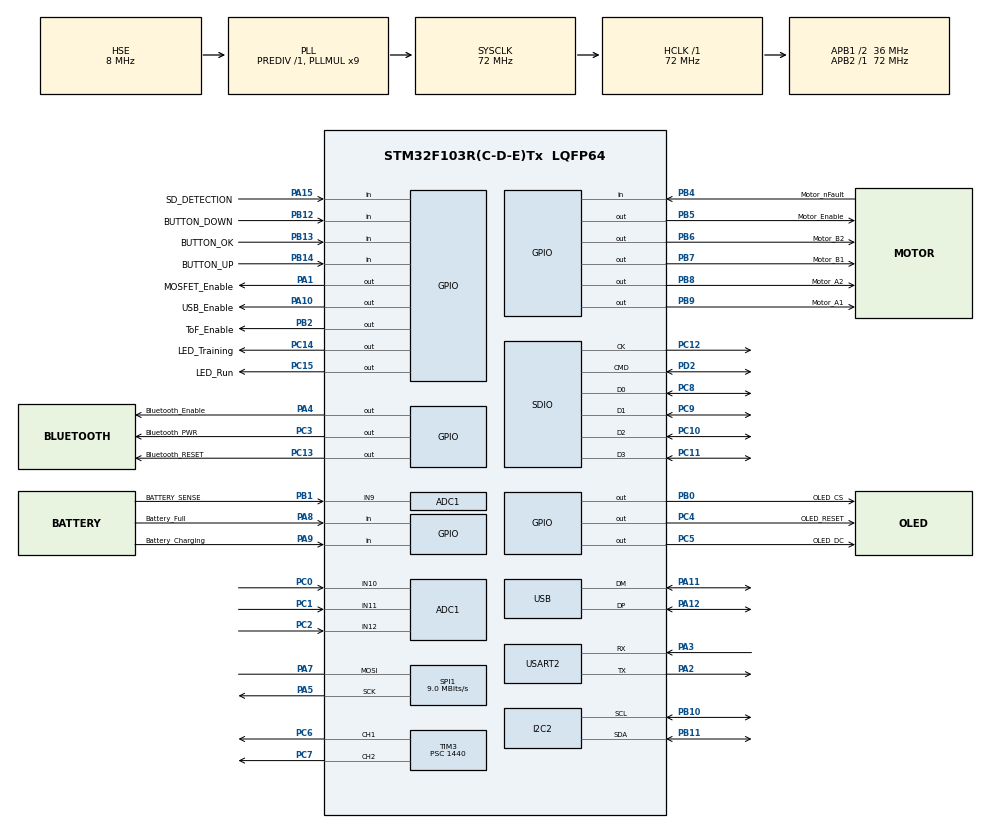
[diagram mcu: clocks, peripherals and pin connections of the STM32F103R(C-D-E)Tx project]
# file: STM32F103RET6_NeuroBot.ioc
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ADC1.Channel-0\#ChannelRegularConversion=ADC_CHANNEL_9
ADC1.Channel-1\#ChannelRegularConversion=ADC_CHANNEL_10
ADC1.Channel-2\#ChannelRegularConversion=ADC_CHANNEL_11
ADC1.Channel-3\#ChannelRegularConversion=ADC_CHANNEL_12
ADC1.ContinuousConvMode=ENABLE
ADC1.DataAlign=ADC_DATAALIGN_RIGHT
ADC1.DiscontinuousConvMode=DISABLE
ADC1.EnableAnalogWatchDog=false
ADC1.EnableRegularConversion=ENABLE
ADC1.ExternalTrigConv=ADC_SOFTWARE_START
ADC1.InjNumberOfConversion=0
ADC1.NbrOfConversion=4
ADC1.NbrOfConversionFlag=1
ADC1.Rank-0\#ChannelRegularConversion=1
ADC1.Rank-1\#ChannelRegularConversion=2
ADC1.Rank-2\#ChannelRegularConversion=3
ADC1.Rank-3\#ChannelRegularConversion=4
ADC1.SamplingTime-0\#ChannelRegularConversion=ADC_SAMPLETIME_239CYCLES_5
ADC1.SamplingTime-1\#ChannelRegularConversion=ADC_SAMPLETIME_239CYCLES_5
ADC1.SamplingTime-2\#ChannelRegularConversion=ADC_SAMPLETIME_239CYCLES_5
ADC1.SamplingTime-3\#ChannelRegularConversion=ADC_SAMPLETIME_239CYCLES_5
ADC1.ScanConvMode=ADC_SCAN_ENABLE
ADC1.master=1
Dma.ADC1.0.Direction=DMA_PERIPH_TO_MEMORY
Dma.ADC1.0.Instance=DMA1_Channel1
Dma.ADC1.0.MemDataAlignment=DMA_MDATAALIGN_WORD
Dma.ADC1.0.MemInc=DMA_MINC_ENABLE
Dma.ADC1.0.Mode=DMA_CIRCULAR
Dma.ADC1.0.PeriphDataAlignment=DMA_PDATAALIGN_WORD
Dma.ADC1.0.PeriphInc=DMA_PINC_DISABLE
Dma.ADC1.0.Priority=DMA_PRIORITY_LOW
Dma.Request0=ADC1
Mcu.Family=STM32F1
Mcu.Name=STM32F103R(C-D-E)Tx
Mcu.Package=LQFP64
NVIC.ADC1_2_IRQn=true\:0\:0\:false\:false\:true\:true
NVIC.DMA1_Channel1_IRQn=true\:0\:0\:false\:false\:true\:false
NVIC.PriorityGroup=NVIC_PRIORITYGROUP_4
NVIC.SDIO_IRQn=true\:0\:0\:false\:false\:true\:true
NVIC.TIM2_IRQn=true\:0\:0\:false\:false\:true\:true
NVIC.USART2_IRQn=true\:0\:0\:false\:false\:true\:true
NVIC.USB_LP_CAN1_RX0_IRQn=true\:0\:0\:false\:false\:true\:true
PA0-WKUP.GPIO_Label=POWER_ON_MAIN
PA0-WKUP.Mode=SYS_WakeUp0
PA0-WKUP.Signal=SYS_WKUP
PA1.GPIO_Label=MOSFET_Enable
PA1.GPIO_Speed=GPIO_SPEED_FREQ_HIGH
PA1.Signal=GPIO_Output
PA10.GPIO_Label=USB_Enable
PA10.GPIO_Speed=GPIO_SPEED_FREQ_HIGH
PA10.Signal=GPIO_Output
PA11.Mode=Device
PA11.Signal=USB_DM
PA12.Mode=Device
PA12.Signal=USB_DP
PA13.Mode=Serial_Wire
PA13.Signal=SYS_JTMS-SWDIO
PA14.Mode=Serial_Wire
PA14.Signal=SYS_JTCK-SWCLK
PA15.GPIO_Label=SD_DETECTION
PA15.GPIO_PuPd=GPIO_PULLUP
PA15.Signal=GPIO_Input
PA2.Mode=Asynchronous
PA2.Signal=USART2_TX
PA3.Mode=Asynchronous
PA3.Signal=USART2_RX
PA4.GPIO_Label=Bluetooth_Enable
PA4.GPIO_Speed=GPIO_SPEED_FREQ_HIGH
PA4.Signal=GPIO_Output
PA5.Mode=Simplex_Bidirectional_Master
PA5.Signal=SPI1_SCK
PA7.Mode=Simplex_Bidirectional_Master
PA7.Signal=SPI1_MOSI
PA8.GPIO_Label=Battery_Full
PA8.GPIO_PuPd=GPIO_PULLUP
PA8.Signal=GPIO_Input
PA9.GPIO_Label=Battery_Charging
PA9.GPIO_PuPd=GPIO_PULLUP
PA9.Signal=GPIO_Input
PB0.GPIO_Label=OLED_CS
PB0.GPIO_Speed=GPIO_SPEED_FREQ_HIGH
PB0.PinState=GPIO_PIN_SET
PB0.Signal=GPIO_Output
PB1.GPIO_Label=BATTERY_SENSE
PB1.Signal=ADCx_IN9
PB10.Mode=I2C
PB10.Signal=I2C2_SCL
PB11.Mode=I2C
PB11.Signal=I2C2_SDA
PB12.GPIO_Label=BUTTON_DOWN
PB12.GPIO_PuPd=GPIO_PULLUP
PB12.Signal=GPIO_Input
PB13.GPIO_Label=BUTTON_OK
PB13.GPIO_PuPd=GPIO_PULLUP
PB13.Signal=GPIO_Input
PB14.GPIO_Label=BUTTON_UP
PB14.GPIO_PuPd=GPIO_PULLUP
PB14.Signal=GPIO_Input
PB2.GPIO_Label=ToF_Enable
PB2.GPIO_Speed=GPIO_SPEED_FREQ_HIGH
PB2.Signal=GPIO_Output
PB4.GPIO_Label=Motor_nFault
PB4.GPIO_PuPd=GPIO_PULLUP
PB4.Signal=GPIO_Input
PB5.GPIO_Label=Motor_Enable
PB5.GPIO_Speed=GPIO_SPEED_FREQ_HIGH
PB5.Signal=GPIO_Output
PB6.GPIO_Label=Motor_B2
PB6.GPIO_Speed=GPIO_SPEED_FREQ_HIGH
PB6.Signal=GPIO_Output
PB7.GPIO_Label=Motor_B1
PB7.GPIO_Speed=GPIO_SPEED_FREQ_HIGH
PB7.Signal=GPIO_Output
PB8.GPIO_Label=Motor_A2
PB8.GPIO_Speed=GPIO_SPEED_FREQ_HIGH
PB8.Signal=GPIO_Output
PB9.GPIO_Label=Motor_A1
PB9.GPIO_Speed=GPIO_SPEED_FREQ_HIGH
PB9.Signal=GPIO_Output
PC0.Signal=ADCx_IN10
PC1.Signal=ADCx_IN11
PC10.Mode=SD_4_bits_Wide_bus
PC10.Signal=SDIO_D2
PC11.Mode=SD_4_bits_Wide_bus
PC11.Signal=SDIO_D3
PC12.Mode=SD_4_bits_Wide_bus
PC12.Signal=SDIO_CK
PC13-TAMPER-RTC.GPIO_Label=Bluetooth_RESET
PC13-TAMPER-RTC.PinState=GPIO_PIN_SET
PC13-TAMPER-RTC.Signal=GPIO_Output
PC14-OSC32_IN.GPIO_Label=LED_Training
PC14-OSC32_IN.GPIO_Speed=GPIO_SPEED_FREQ_HIGH
PC14-OSC32_IN.Signal=GPIO_Output
PC15-OSC32_OUT.GPIO_Label=LED_Run
PC15-OSC32_OUT.GPIO_Speed=GPIO_SPEED_FREQ_HIGH
PC15-OSC32_OUT.Signal=GPIO_Output
PC2.Signal=ADCx_IN12
PC3.GPIO_Label=Bluetooth_PWR
PC3.PinState=GPIO_PIN_SET
PC3.Signal=GPIO_Output
PC4.GPIO_Label=OLED_RESET
PC4.GPIO_Speed=GPIO_SPEED_FREQ_HIGH
PC4.Signal=GPIO_Output
PC5.GPIO_Label=OLED_DC
PC5.GPIO_Speed=GPIO_SPEED_FREQ_HIGH
PC5.Signal=GPIO_Output
PC6.Signal=S_TIM3_CH1
PC7.Signal=S_TIM3_CH2
PC8.Mode=SD_4_bits_Wide_bus
PC8.Signal=SDIO_D0
PC9.Mode=SD_4_bits_Wide_bus
PC9.Signal=SDIO_D1
PD0-OSC_IN.Mode=HSE-External-Oscillator
PD0-OSC_IN.Signal=RCC_OSC_IN
PD1-OSC_OUT.Mode=HSE-External-Oscillator
PD1-OSC_OUT.Signal=RCC_OSC_OUT
PD2.Mode=SD_4_bits_Wide_bus
PD2.Signal=SDIO_CMD
ProjectManager.HeapSize=0x2000
ProjectManager.StackSize=0x4000
ProjectManager.TargetToolchain=SW4STM32
RCC.ADCPresc=RCC_ADCPCLK2_DIV6
RCC.AHBFreq_Value=72000000
RCC.APB1CLKDivider=RCC_HCLK_DIV2
RCC.APB1Freq_Value=36000000
RCC.APB1TimFreq_Value=72000000
RCC.APB2Freq_Value=72000000
RCC.APB2TimFreq_Value=72000000
RCC.HCLKFreq_Value=72000000
RCC.PLLMUL=RCC_PLL_MUL9
RCC.SYSCLKFreq_VALUE=72000000
RCC.SYSCLKSource=RCC_SYSCLKSOURCE_PLLCLK
RCC.USBFreq_Value=48000000
RCC.USBPrescaler=RCC_USBCLKSOURCE_PLL_DIV1_5
SDIO.ClockDiv=24
SH.ADCx_IN10.0=ADC1_IN10,IN10
SH.ADCx_IN11.0=ADC1_IN11,IN11
SH.ADCx_IN12.0=ADC1_IN12,IN12
SH.ADCx_IN9.0=ADC1_IN9,IN9
SH.S_TIM3_CH1.0=TIM3_CH1,PWM Generation1 CH1
SH.S_TIM3_CH2.0=TIM3_CH2,PWM Generation2 CH2
SPI1.BaudRatePrescaler=SPI_BAUDRATEPRESCALER_8
SPI1.CalculateBaudRate=9.0 MBits/s
SPI1.Direction=SPI_DIRECTION_1LINE
SPI1.Mode=SPI_MODE_MASTER
SPI1.VirtualType=VM_MASTER
TIM2.Period=1999
TIM2.Prescaler=720
TIM3.Channel-PWM\ Generation1\ CH1=TIM_CHANNEL_1
TIM3.Channel-PWM\ Generation2\ CH2=TIM_CHANNEL_2
TIM3.Period=999
TIM3.Prescaler=1440
TIM3.Pulse-PWM\ Generation1\ CH1=75
TIM3.Pulse-PWM\ Generation2\ CH2=51
USART2.VirtualMode=VM_ASYNC
USB_DEVICE.CLASS_NAME_FS=MSC
USB_DEVICE.MANUFACTURER_STRING=Cyberpunk technologies s.r.o.
USB_DEVICE.PRODUCT_STRING_MSC_FS=NeuroBot Mass Storage
USB_DEVICE.USBD_HandleTypeDef=hUsbDeviceFS
USB_DEVICE.VirtualMode=Msc
USB_DEVICE.VirtualModeFS=Msc_FS
VP_FATFS_VS_SDIO.Mode=SDIO
VP_TIM2_VS_ClockSourceINT.Mode=Internal
VP_TIM3_VS_ClockSourceINT.Mode=Internal
VP_USB_DEVICE_VS_USB_DEVICE_MSC_FS.Mode=MSC_FS
board=STM32F103RET6_AIM_1.0

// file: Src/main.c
/**
  ******************************************************************************
  * File Name          : main.c
  * Description        : Main program body
  ******************************************************************************
  * This notice applies to any and all portions of this file
  * that are not between comment pairs USER CODE BEGIN and
  * USER CODE END. Other portions of this file, whether
  * inserted by the user or by software development tools
  * are owned by their respective copyright owners.
  *
  * Copyright (c) 2018 STMicroelectronics International N.V.
  * All rights reserved.
  *
  * Redistribution and use in source and binary forms, with or without
  * modification, are permitted, provided that the following conditions are met:
  *
  * 1. Redistribution of source code must retain the above copyright notice,
  *    this list of conditions and the following disclaimer.
  * 2. Redistributions in binary form must reproduce the above copyright notice,
  *    this list of conditions and the following disclaimer in the documentation
  *    and/or other materials provided with the distribution.
  * 3. Neither the name of STMicroelectronics nor the names of other
  *    contributors to this software may be used to endorse or promote products
  *    derived from this software without specific written permission.
  * 4. This software, including modifications and/or derivative works of this
  *    software, must execute solely and exclusively on microcontroller or
  *    microprocessor devices manufactured by or for STMicroelectronics.
  * 5. Redistribution and use of this software other than as permitted under
  *    this license is void and will automatically terminate your rights under
  *    this license.
  *
  * THIS SOFTWARE IS PROVIDED BY STMICROELECTRONICS AND CONTRIBUTORS "AS IS"
  * AND ANY EXPRESS, IMPLIED OR STATUTORY WARRANTIES, INCLUDING, BUT NOT
  * LIMITED TO, THE IMPLIED WARRANTIES OF MERCHANTABILITY, FITNESS FOR A
  * PARTICULAR PURPOSE AND NON-INFRINGEMENT OF THIRD PARTY INTELLECTUAL PROPERTY
  * RIGHTS ARE DISCLAIMED TO THE FULLEST EXTENT PERMITTED BY LAW. IN NO EVENT
  * SHALL STMICROELECTRONICS OR CONTRIBUTORS BE LIABLE FOR ANY DIRECT, INDIRECT,
  * INCIDENTAL, SPECIAL, EXEMPLARY, OR CONSEQUENTIAL DAMAGES (INCLUDING, BUT NOT
  * LIMITED TO, PROCUREMENT OF SUBSTITUTE GOODS OR SERVICES; LOSS OF USE, DATA,
  * OR PROFITS; OR BUSINESS INTERRUPTION) HOWEVER CAUSED AND ON ANY THEORY OF
  * LIABILITY, WHETHER IN CONTRACT, STRICT LIABILITY, OR TORT (INCLUDING
  * NEGLIGENCE OR OTHERWISE) ARISING IN ANY WAY OUT OF THE USE OF THIS SOFTWARE,
  * EVEN IF ADVISED OF THE POSSIBILITY OF SUCH DAMAGE.
  *
  ******************************************************************************
  */
#include "main.h"
#include "stm32f1xx_hal.h"
#include "fatfs.h"
#include "usb_device.h"

/* USER CODE BEGIN Includes */
#include "NeuroBot.h"
/* USER CODE END Includes */

ADC_HandleTypeDef hadc1;
DMA_HandleTypeDef hdma_adc1;

I2C_HandleTypeDef hi2c2;

SD_HandleTypeDef hsd;
HAL_SD_CardInfoTypedef SDCardInfo;

SPI_HandleTypeDef hspi1;

TIM_HandleTypeDef htim2;
TIM_HandleTypeDef htim3;

UART_HandleTypeDef huart2;

/* USER CODE BEGIN PV */
/* Private variables ---------------------------------------------------------*/

/* USER CODE END PV */

void SystemClock_Config(void);
static void MX_GPIO_Init(void);
static void MX_DMA_Init(void);
static void MX_ADC1_Init(void);
static void MX_SDIO_SD_Init(void);
static void MX_TIM2_Init(void);
static void MX_TIM3_Init(void);
static void MX_I2C2_Init(void);
static void MX_SPI1_Init(void);
static void MX_USART2_UART_Init(void);

void HAL_TIM_MspPostInit(TIM_HandleTypeDef *htim);

/* USER CODE BEGIN PFP */
/* Private function prototypes -----------------------------------------------*/

/* USER CODE END PFP */

int main(void)
{

  /* MCU Configuration----------------------------------------------------------*/

  /* Reset of all peripherals, Initializes the Flash interface and the Systick. */
  HAL_Init();

  /* Configure the system clock */
  SystemClock_Config();

  /* Initialize all configured peripherals */
  MX_GPIO_Init();
  MX_DMA_Init();
  MX_ADC1_Init();
  MX_SDIO_SD_Init();
  MX_TIM2_Init();
  MX_TIM3_Init();
  MX_FATFS_Init();
  MX_USB_DEVICE_Init();
  MX_I2C2_Init();
  MX_SPI1_Init();
  MX_USART2_UART_Init();

  /* USER CODE BEGIN 2 */
	NeuroBot_init();
  /* USER CODE END 2 */

  /* Infinite loop */
  while (1)
  {

  /* USER CODE BEGIN 3 */
	menu_manager();
  }
  /* USER CODE END 3 */

}

/** System Clock Configuration
*/
void SystemClock_Config(void)
{

  RCC_OscInitTypeDef RCC_OscInitStruct;
  RCC_ClkInitTypeDef RCC_ClkInitStruct;
  RCC_PeriphCLKInitTypeDef PeriphClkInit;

    /**Initializes the CPU, AHB and APB busses clocks
    */
  RCC_OscInitStruct.OscillatorType = RCC_OSCILLATORTYPE_HSE;
  RCC_OscInitStruct.HSEState = RCC_HSE_ON;
  RCC_OscInitStruct.HSEPredivValue = RCC_HSE_PREDIV_DIV1;
  RCC_OscInitStruct.HSIState = RCC_HSI_ON;
  RCC_OscInitStruct.PLL.PLLState = RCC_PLL_ON;
  RCC_OscInitStruct.PLL.PLLSource = RCC_PLLSOURCE_HSE;
  RCC_OscInitStruct.PLL.PLLMUL = RCC_PLL_MUL9;
  if (HAL_RCC_OscConfig(&RCC_OscInitStruct) != HAL_OK)
  {
    _Error_Handler(__FILE__, __LINE__);
  }

    /**Initializes the CPU, AHB and APB busses clocks
    */
  RCC_ClkInitStruct.ClockType = RCC_CLOCKTYPE_HCLK|RCC_CLOCKTYPE_SYSCLK
                              |RCC_CLOCKTYPE_PCLK1|RCC_CLOCKTYPE_PCLK2;
  RCC_ClkInitStruct.SYSCLKSource = RCC_SYSCLKSOURCE_PLLCLK;
  RCC_ClkInitStruct.AHBCLKDivider = RCC_SYSCLK_DIV1;
  RCC_ClkInitStruct.APB1CLKDivider = RCC_HCLK_DIV2;
  RCC_ClkInitStruct.APB2CLKDivider = RCC_HCLK_DIV1;

  if (HAL_RCC_ClockConfig(&RCC_ClkInitStruct, FLASH_LATENCY_2) != HAL_OK)
  {
    _Error_Handler(__FILE__, __LINE__);
  }

  PeriphClkInit.PeriphClockSelection = RCC_PERIPHCLK_ADC|RCC_PERIPHCLK_USB;
  PeriphClkInit.AdcClockSelection = RCC_ADCPCLK2_DIV6;
  PeriphClkInit.UsbClockSelection = RCC_USBCLKSOURCE_PLL_DIV1_5;
  if (HAL_RCCEx_PeriphCLKConfig(&PeriphClkInit) != HAL_OK)
  {
    _Error_Handler(__FILE__, __LINE__);
  }

    /**Configure the Systick interrupt time
    */
  HAL_SYSTICK_Config(HAL_RCC_GetHCLKFreq()/1000);

    /**Configure the Systick
    */
  HAL_SYSTICK_CLKSourceConfig(SYSTICK_CLKSOURCE_HCLK);

  /* SysTick_IRQn interrupt configuration */
  HAL_NVIC_SetPriority(SysTick_IRQn, 0, 0);
}

/* ADC1 init function */
static void MX_ADC1_Init(void)
{

  ADC_ChannelConfTypeDef sConfig;

    /**Common config
    */
  hadc1.Instance = ADC1;
  hadc1.Init.ScanConvMode = ADC_SCAN_ENABLE;
  hadc1.Init.ContinuousConvMode = ENABLE;
  hadc1.Init.DiscontinuousConvMode = DISABLE;
  hadc1.Init.ExternalTrigConv = ADC_SOFTWARE_START;
  hadc1.Init.DataAlign = ADC_DATAALIGN_RIGHT;
  hadc1.Init.NbrOfConversion = 4;
  if (HAL_ADC_Init(&hadc1) != HAL_OK)
  {
    _Error_Handler(__FILE__, __LINE__);
  }

    /**Configure Regular Channel
    */
  sConfig.Channel = ADC_CHANNEL_9;
  sConfig.Rank = 1;
  sConfig.SamplingTime = ADC_SAMPLETIME_239CYCLES_5;
  if (HAL_ADC_ConfigChannel(&hadc1, &sConfig) != HAL_OK)
  {
    _Error_Handler(__FILE__, __LINE__);
  }

    /**Configure Regular Channel
    */
  sConfig.Channel = ADC_CHANNEL_10;
  sConfig.Rank = 2;
  if (HAL_ADC_ConfigChannel(&hadc1, &sConfig) != HAL_OK)
  {
    _Error_Handler(__FILE__, __LINE__);
  }

    /**Configure Regular Channel
    */
  sConfig.Channel = ADC_CHANNEL_11;
  sConfig.Rank = 3;
  if (HAL_ADC_ConfigChannel(&hadc1, &sConfig) != HAL_OK)
  {
    _Error_Handler(__FILE__, __LINE__);
  }

  /**Configure Regular Channel
  */
  sConfig.Channel = ADC_CHANNEL_12;
  sConfig.Rank = 4;
  if (HAL_ADC_ConfigChannel(&hadc1, &sConfig) != HAL_OK)
  {
    _Error_Handler(__FILE__, __LINE__);
  }

}

/* I2C2 init function */
static void MX_I2C2_Init(void)
{

  hi2c2.Instance = I2C2;
  hi2c2.Init.ClockSpeed = 100000;
  hi2c2.Init.DutyCycle = I2C_DUTYCYCLE_2;
  hi2c2.Init.OwnAddress1 = 0;
  hi2c2.Init.AddressingMode = I2C_ADDRESSINGMODE_7BIT;
  hi2c2.Init.DualAddressMode = I2C_DUALADDRESS_DISABLE;
  hi2c2.Init.OwnAddress2 = 0;
  hi2c2.Init.GeneralCallMode = I2C_GENERALCALL_DISABLE;
  hi2c2.Init.NoStretchMode = I2C_NOSTRETCH_DISABLE;
  if (HAL_I2C_Init(&hi2c2) != HAL_OK)
  {
    _Error_Handler(__FILE__, __LINE__);
  }

}

/* SDIO init function */
static void MX_SDIO_SD_Init(void)
{

  hsd.Instance = SDIO;
  hsd.Init.ClockEdge = SDIO_CLOCK_EDGE_RISING;
  hsd.Init.ClockBypass = SDIO_CLOCK_BYPASS_DISABLE;
  hsd.Init.ClockPowerSave = SDIO_CLOCK_POWER_SAVE_DISABLE;
  hsd.Init.BusWide = SDIO_BUS_WIDE_1B;
  hsd.Init.HardwareFlowControl = SDIO_HARDWARE_FLOW_CONTROL_DISABLE;
  hsd.Init.ClockDiv = 24;

}

/* SPI1 init function */
static void MX_SPI1_Init(void)
{

  hspi1.Instance = SPI1;
  hspi1.Init.Mode = SPI_MODE_MASTER;
  hspi1.Init.Direction = SPI_DIRECTION_1LINE;
  hspi1.Init.DataSize = SPI_DATASIZE_8BIT;
  hspi1.Init.CLKPolarity = SPI_POLARITY_LOW;
  hspi1.Init.CLKPhase = SPI_PHASE_1EDGE;
  hspi1.Init.NSS = SPI_NSS_SOFT;
  hspi1.Init.BaudRatePrescaler = SPI_BAUDRATEPRESCALER_8;
  hspi1.Init.FirstBit = SPI_FIRSTBIT_MSB;
  hspi1.Init.TIMode = SPI_TIMODE_DISABLE;
  hspi1.Init.CRCCalculation = SPI_CRCCALCULATION_DISABLE;
  hspi1.Init.CRCPolynomial = 10;
  if (HAL_SPI_Init(&hspi1) != HAL_OK)
  {
    _Error_Handler(__FILE__, __LINE__);
  }

}

/* TIM2 init function */
static void MX_TIM2_Init(void)
{

  TIM_ClockConfigTypeDef sClockSourceConfig;
  TIM_MasterConfigTypeDef sMasterConfig;

  htim2.Instance = TIM2;
  htim2.Init.Prescaler = 720;
  htim2.Init.CounterMode = TIM_COUNTERMODE_UP;
  htim2.Init.Period = 1999;
  htim2.Init.ClockDivision = TIM_CLOCKDIVISION_DIV1;
  if (HAL_TIM_Base_Init(&htim2) != HAL_OK)
  {
    _Error_Handler(__FILE__, __LINE__);
  }

  sClockSourceConfig.ClockSource = TIM_CLOCKSOURCE_INTERNAL;
  if (HAL_TIM_ConfigClockSource(&htim2, &sClockSourceConfig) != HAL_OK)
  {
    _Error_Handler(__FILE__, __LINE__);
  }

  sMasterConfig.MasterOutputTrigger = TIM_TRGO_RESET;
  sMasterConfig.MasterSlaveMode = TIM_MASTERSLAVEMODE_DISABLE;
  if (HAL_TIMEx_MasterConfigSynchronization(&htim2, &sMasterConfig) != HAL_OK)
  {
    _Error_Handler(__FILE__, __LINE__);
  }

}

/* TIM3 init function */
static void MX_TIM3_Init(void)
{

  TIM_ClockConfigTypeDef sClockSourceConfig;
  TIM_MasterConfigTypeDef sMasterConfig;
  TIM_OC_InitTypeDef sConfigOC;

  htim3.Instance = TIM3;
  htim3.Init.Prescaler = 1440;
  htim3.Init.CounterMode = TIM_COUNTERMODE_UP;
  htim3.Init.Period = 999;
  htim3.Init.ClockDivision = TIM_CLOCKDIVISION_DIV1;
  if (HAL_TIM_Base_Init(&htim3) != HAL_OK)
  {
    _Error_Handler(__FILE__, __LINE__);
  }

  sClockSourceConfig.ClockSource = TIM_CLOCKSOURCE_INTERNAL;
  if (HAL_TIM_ConfigClockSource(&htim3, &sClockSourceConfig) != HAL_OK)
  {
    _Error_Handler(__FILE__, __LINE__);
  }

  if (HAL_TIM_PWM_Init(&htim3) != HAL_OK)
  {
    _Error_Handler(__FILE__, __LINE__);
  }

  sMasterConfig.MasterOutputTrigger = TIM_TRGO_RESET;
  sMasterConfig.MasterSlaveMode = TIM_MASTERSLAVEMODE_DISABLE;
  if (HAL_TIMEx_MasterConfigSynchronization(&htim3, &sMasterConfig) != HAL_OK)
  {
    _Error_Handler(__FILE__, __LINE__);
  }

  sConfigOC.OCMode = TIM_OCMODE_PWM1;
  sConfigOC.Pulse = 75;
  sConfigOC.OCPolarity = TIM_OCPOLARITY_HIGH;
  sConfigOC.OCFastMode = TIM_OCFAST_DISABLE;
  if (HAL_TIM_PWM_ConfigChannel(&htim3, &sConfigOC, TIM_CHANNEL_1) != HAL_OK)
  {
    _Error_Handler(__FILE__, __LINE__);
  }

  sConfigOC.Pulse = 51;
  if (HAL_TIM_PWM_ConfigChannel(&htim3, &sConfigOC, TIM_CHANNEL_2) != HAL_OK)
  {
    _Error_Handler(__FILE__, __LINE__);
  }

  HAL_TIM_MspPostInit(&htim3);

}

/* USART2 init function */
static void MX_USART2_UART_Init(void)
{

  huart2.Instance = USART2;
  huart2.Init.BaudRate = 115200;
  huart2.Init.WordLength = UART_WORDLENGTH_8B;
  huart2.Init.StopBits = UART_STOPBITS_1;
  huart2.Init.Parity = UART_PARITY_NONE;
  huart2.Init.Mode = UART_MODE_TX_RX;
  huart2.Init.HwFlowCtl = UART_HWCONTROL_NONE;
  huart2.Init.OverSampling = UART_OVERSAMPLING_16;
  if (HAL_UART_Init(&huart2) != HAL_OK)
  {
    _Error_Handler(__FILE__, __LINE__);
  }

}

static void MX_DMA_Init(void)
{
  /* DMA controller clock enable */
  __HAL_RCC_DMA1_CLK_ENABLE();

  /* DMA interrupt init */
  /* DMA1_Channel1_IRQn interrupt configuration */
  HAL_NVIC_SetPriority(DMA1_Channel1_IRQn, 0, 0);
  HAL_NVIC_EnableIRQ(DMA1_Channel1_IRQn);

}

/** Configure pins as
        * Analog
        * Input
        * Output
        * EVENT_OUT
        * EXTI
*/
static void MX_GPIO_Init(void)
{

  GPIO_InitTypeDef GPIO_InitStruct;

  /* GPIO Ports Clock Enable */
  __HAL_RCC_GPIOC_CLK_ENABLE();
  __HAL_RCC_GPIOD_CLK_ENABLE();
  __HAL_RCC_GPIOA_CLK_ENABLE();
  __HAL_RCC_GPIOB_CLK_ENABLE();

  /*Configure GPIO pin Output Level */
  HAL_GPIO_WritePin(GPIOC, Bluetooth_RESET_Pin|Bluetooth_PWR_Pin, GPIO_PIN_SET);

  /*Configure GPIO pin Output Level */
  HAL_GPIO_WritePin(GPIOC, LED_Training_Pin|LED_Run_Pin|OLED_RESET_Pin|OLED_DC_Pin, GPIO_PIN_RESET);

  /*Configure GPIO pin Output Level */
  HAL_GPIO_WritePin(GPIOA, MOSFET_Enable_Pin|Bluetooth_Enable_Pin|USB_Enable_Pin, GPIO_PIN_RESET);

  /*Configure GPIO pin Output Level */
  HAL_GPIO_WritePin(OLED_CS_GPIO_Port, OLED_CS_Pin, GPIO_PIN_SET);

  /*Configure GPIO pin Output Level */
  HAL_GPIO_WritePin(GPIOB, ToF_Enable_Pin|Motor_Enable_Pin|Motor_B2_Pin|Motor_B1_Pin
                          |Motor_A2_Pin|Motor_A1_Pin, GPIO_PIN_RESET);

  /*Configure GPIO pins : Bluetooth_RESET_Pin Bluetooth_PWR_Pin */
  GPIO_InitStruct.Pin = Bluetooth_RESET_Pin|Bluetooth_PWR_Pin;
  GPIO_InitStruct.Mode = GPIO_MODE_OUTPUT_PP;
  GPIO_InitStruct.Speed = GPIO_SPEED_FREQ_LOW;
  HAL_GPIO_Init(GPIOC, &GPIO_InitStruct);

  /*Configure GPIO pins : LED_Training_Pin LED_Run_Pin OLED_RESET_Pin OLED_DC_Pin */
  GPIO_InitStruct.Pin = LED_Training_Pin|LED_Run_Pin|OLED_RESET_Pin|OLED_DC_Pin;
  GPIO_InitStruct.Mode = GPIO_MODE_OUTPUT_PP;
  GPIO_InitStruct.Speed = GPIO_SPEED_FREQ_HIGH;
  HAL_GPIO_Init(GPIOC, &GPIO_InitStruct);

  /*Configure GPIO pins : MOSFET_Enable_Pin Bluetooth_Enable_Pin USB_Enable_Pin */
  GPIO_InitStruct.Pin = MOSFET_Enable_Pin|Bluetooth_Enable_Pin|USB_Enable_Pin;
  GPIO_InitStruct.Mode = GPIO_MODE_OUTPUT_PP;
  GPIO_InitStruct.Speed = GPIO_SPEED_FREQ_HIGH;
  HAL_GPIO_Init(GPIOA, &GPIO_InitStruct);

  /*Configure GPIO pins : OLED_CS_Pin ToF_Enable_Pin Motor_Enable_Pin Motor_B2_Pin
                           Motor_B1_Pin Motor_A2_Pin Motor_A1_Pin */
  GPIO_InitStruct.Pin = OLED_CS_Pin|ToF_Enable_Pin|Motor_Enable_Pin|Motor_B2_Pin
                          |Motor_B1_Pin|Motor_A2_Pin|Motor_A1_Pin;
  GPIO_InitStruct.Mode = GPIO_MODE_OUTPUT_PP;
  GPIO_InitStruct.Speed = GPIO_SPEED_FREQ_HIGH;
  HAL_GPIO_Init(GPIOB, &GPIO_InitStruct);

  /*Configure GPIO pins : BUTTON_DOWN_Pin BUTTON_OK_Pin BUTTON_UP_Pin Motor_nFault_Pin */
  GPIO_InitStruct.Pin = BUTTON_DOWN_Pin|BUTTON_OK_Pin|BUTTON_UP_Pin|Motor_nFault_Pin;
  GPIO_InitStruct.Mode = GPIO_MODE_INPUT;
  GPIO_InitStruct.Pull = GPIO_PULLUP;
  HAL_GPIO_Init(GPIOB, &GPIO_InitStruct);

  /*Configure GPIO pins : Battery_Full_Pin Battery_Charging_Pin SD_DETECTION_Pin */
  GPIO_InitStruct.Pin = Battery_Full_Pin|Battery_Charging_Pin|SD_DETECTION_Pin;
  GPIO_InitStruct.Mode = GPIO_MODE_INPUT;
  GPIO_InitStruct.Pull = GPIO_PULLUP;
  HAL_GPIO_Init(GPIOA, &GPIO_InitStruct);

}

void _Error_Handler(char * file, int line)
{
  while(1)
  {
  }
}

/************************ (C) COPYRIGHT STMicroelectronics *****END OF FILE****/
